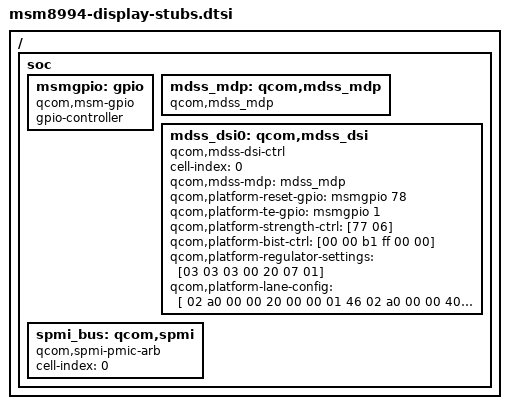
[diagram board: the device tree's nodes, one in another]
/ {
	soc {
		msmgpio: gpio {
			compatible = "qcom,msm-gpio";
			gpio-controller;
			#gpio-cells = <2>;
		};

		mdss_mdp: qcom,mdss_mdp {
			compatible = "qcom,mdss_mdp";
		};

		mdss_dsi0: qcom,mdss_dsi {
			compatible = "qcom,mdss-dsi-ctrl";
			cell-index = <0>;
			qcom,mdss-mdp = <&mdss_mdp>;
			qcom,platform-reset-gpio = <&msmgpio 78 0>;
			//qcom,platform-enable-gpio = <&pm8994_gpios 14 0>;
			qcom,platform-te-gpio = <&msmgpio 1 0>;
			qcom,platform-strength-ctrl = [77 06];
			qcom,platform-bist-ctrl = [00 00 b1 ff 00 00];
			qcom,platform-regulator-settings = [03 03 03 00 20 07 01];
			qcom,platform-lane-config = [
				02 a0 00 00 20 00 00 01 46
				02 a0 00 00 40 00 00 01 46
				02 a0 00 40 20 00 00 01 46
				02 a0 00 40 00 00 00 01 46
				00 a0 00 80 00 00 00 01 46
			];
		};

		spmi_bus: qcom,spmi {
			compatible = "qcom,spmi-pmic-arb";
			cell-index = <0>;
			#address-cells = <1>;
			#size-cells = <0>;
		};
	};
};
